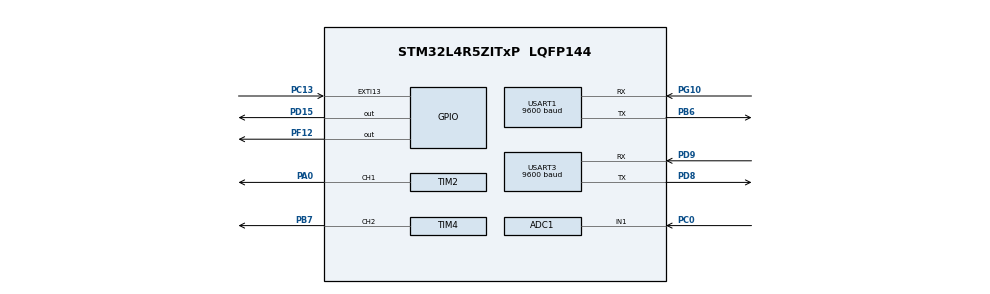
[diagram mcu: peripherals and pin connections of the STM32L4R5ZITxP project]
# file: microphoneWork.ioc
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ADC1.AWD1HighThreshold=3289
ADC1.AWD1ITMode=ENABLE
ADC1.Channel-0\#ChannelRegularConversion=ADC_CHANNEL_1
ADC1.ClockPrescaler=ADC_CLOCK_ASYNC_DIV32
ADC1.ContinuousConvMode=ENABLE
ADC1.EnableAnalogWatchDog1=true
ADC1.EnableAnalogWatchDog2=false
ADC1.NbrOfConversionFlag=1
ADC1.OffsetNumber-0\#ChannelRegularConversion=ADC_OFFSET_NONE
ADC1.Rank-0\#ChannelRegularConversion=1
ADC1.SamplingTime-0\#ChannelRegularConversion=ADC_SAMPLETIME_640CYCLES_5
ADC1.WatchdogChannel=ADC_CHANNEL_1
ADC1.master=1
Mcu.Family=STM32L4
Mcu.Name=STM32L4R5ZITxP
Mcu.Package=LQFP144
NVIC.ADC1_IRQn=true\:0\:0\:false\:false\:true\:true\:true\:true
NVIC.EXTI15_10_IRQn=true\:0\:0\:false\:false\:true\:true\:true\:true
NVIC.PriorityGroup=NVIC_PRIORITYGROUP_4
PA0.Signal=S_TIM2_CH1
PA1.Signal=ADCx_IN6
PA10.Signal=USB_OTG_FS_ID
PA13\ (JTMS/SWDIO).Signal=SYS_JTMS-SWDIO
PA14\ (JTCK/SWCLK).Signal=SYS_JTCK-SWCLK
PA3.Signal=ADCx_IN8
PA4.Signal=SPI1_NSS
PA5.Signal=SPI1_SCK
PA6.Signal=SPI1_MISO
PA7.Signal=SPI1_MOSI
PA8.Signal=USB_OTG_FS_SOF
PA9.Signal=USB_OTG_FS_VBUS
PB0.Signal=S_TIM3_CH3
PB1.Signal=ADCx_IN16
PB10.Signal=S_TIM2_CH3
PB12.Signal=SAI2_FS_A
PB13.Signal=SAI2_SCK_A
PB14.Signal=S_TIM15_CH1
PB15.Signal=SAI2_SD_A
PB2.Signal=COMP1_INP
PB3\ (JTDO/TRACESWO).Signal=SPI3_SCK
PB4\ (NJTRST).Signal=SPI3_MISO
PB5.Signal=SPI3_MOSI
PB6.Mode=Asynchronous
PB6.Signal=USART1_TX
PB7.Signal=S_TIM4_CH2
PB8.Signal=I2C1_SCL
PB9.Signal=I2C1_SDA
PC0.Signal=ADCx_IN1
PC1.Signal=ADCx_IN2
PC10.Signal=SDMMC1_D2
PC11.Signal=SDMMC1_D3
PC12.Signal=SDMMC1_CK
PC13.Signal=GPXTI13
PC14-OSC32_IN\ (PC14).Signal=RCC_OSC32_IN
PC15-OSC32_OUT\ (PC15).Signal=RCC_OSC32_OUT
PC2.Signal=ADCx_IN3
PC3.Signal=ADCx_IN4
PC4.Signal=ADCx_IN13
PC5.Signal=ADCx_IN14
PC6.Signal=SAI2_MCLK_A
PC7.Signal=S_TIM3_CH2
PC8.Signal=SDMMC1_D0
PC9.Signal=SDMMC1_D1
PD0.Signal=CAN1_RX
PD14.Signal=S_TIM4_CH3
PD15.Signal=GPIO_Output
PD2.Signal=SDMMC1_CMD
PD3.Signal=USART2_CTS
PD4.Signal=USART2_RTS
PD5.Signal=USART2_TX
PD6.Signal=USART2_RX
PD8.Mode=Asynchronous
PD8.Signal=USART3_TX
PD9.Mode=Asynchronous
PD9.Signal=USART3_RX
PE0.Signal=S_TIM4_ETR
PE10.Signal=TIM1_CH2N
PE11.Signal=S_TIM1_CH2
PE12.Signal=TIM1_CH3N
PE13.Signal=S_TIM1_CH3
PE14.Signal=TIM1_BKIN2
PE15.Signal=TIM1_BKIN
PE2.Signal=SAI1_MCLK_A
PE3.Signal=SAI1_SD_B
PE7.Signal=S_TIM1_ETR
PE8.Signal=TIM1_CH1N
PF0.Signal=I2C2_SDA
PF1.Signal=I2C2_SCL
PF12.Signal=GPIO_Output
PF2.Signal=I2C2_SMBA
PF7.Signal=SAI1_MCLK_B
PG10.Mode=Asynchronous
PG10.Signal=USART1_RX
PG7.Signal=LPUART1_TX
PG8.Signal=LPUART1_RX
PH0-OSC_IN\ (PH0).Signal=RCC_OSC_IN
PH1-OSC_OUT\ (PH1).Signal=RCC_OSC_OUT
ProjectManager.HeapSize=0x200
ProjectManager.StackSize=0x400
ProjectManager.TargetToolchain=STM32CubeIDE
RCC.ADCFreq_Value=32000000
RCC.HSE_VALUE=8000000
RCC.HSI48_VALUE=48000000
RCC.HSI_VALUE=16000000
RCC.LSE_VALUE=32768
RCC.MSI_VALUE=4000000
RCC.PLLSAI1N=16
RCC.USBFreq_Value=32000000
RCC.VCOOutputFreq_Value=32000000
SH.ADCx_IN1.0=ADC1_IN1,IN1-Single-Ended
SH.ADCx_IN13.0=ADC1_IN13
SH.ADCx_IN14.0=ADC1_IN14
SH.ADCx_IN16.0=ADC1_IN16
SH.ADCx_IN2.0=ADC1_IN2
SH.ADCx_IN3.0=ADC1_IN3
SH.ADCx_IN4.0=ADC1_IN4
SH.ADCx_IN6.0=ADC1_IN6
SH.ADCx_IN8.0=ADC1_IN8
SH.S_TIM15_CH1.0=TIM15_CH1
SH.S_TIM1_CH2.0=TIM1_CH2
SH.S_TIM1_CH3.0=TIM1_CH3
SH.S_TIM1_ETR.0=TIM1_ETR
SH.S_TIM2_CH1.0=TIM2_CH1,PWM Generation1 CH1
SH.S_TIM2_CH3.0=TIM2_CH3
SH.S_TIM3_CH2.0=TIM3_CH2
SH.S_TIM3_CH3.0=TIM3_CH3
SH.S_TIM4_CH2.0=TIM4_CH2,PWM Generation2 CH2
SH.S_TIM4_CH3.0=TIM4_CH3
SH.S_TIM4_ETR.0=TIM4_ETR
TIM2.Channel-PWM\ Generation1\ CH1=TIM_CHANNEL_1
TIM4.AutoReloadPreload=TIM_AUTORELOAD_PRELOAD_ENABLE
TIM4.Channel-PWM\ Generation2\ CH2=TIM_CHANNEL_2
TIM4.Prescaler=159
USART1.BaudRate=9600
USART1.FIFOMode=FIFOMODE_ENABLE
USART1.RXFIFOThreshold=RXFIFO_THRESHOLD_FULL
USART1.VirtualMode-Asynchronous=VM_ASYNC
USART3.BaudRate=9600
USART3.FIFOMode=FIFOMODE_ENABLE
USART3.RXFIFOThreshold=RXFIFO_THRESHOLD_FULL
USART3.VirtualMode-Asynchronous=VM_ASYNC
VP_IWDG_VS_IWDG.Mode=IWDG_Activate
VP_TIM4_VS_ClockSourceINT.Mode=Internal
board=NUCLEO-L4R5ZI-P

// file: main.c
/* USER CODE BEGIN Header */
/**
  ******************************************************************************
  * @file           : main.c
  * @brief          : Main program body
  ******************************************************************************
  * @attention
  *
  * Copyright (c) 2023 STMicroelectronics.
  * All rights reserved.
  *
  * This software is licensed under terms that can be found in the LICENSE file
  * in the root directory of this software component.
  * If no LICENSE file comes with this software, it is provided AS-IS.
  *
  ******************************************************************************
  */
/* USER CODE END Header */
#include "main.h"

/* USER CODE BEGIN Includes */
#include "XBEE.h"
#include "Unit.h"
#include "Typedefs.h"
/* USER CODE END Includes */

ADC_HandleTypeDef hadc1;

IWDG_HandleTypeDef hiwdg;

TIM_HandleTypeDef htim2;
TIM_HandleTypeDef htim4;

UART_HandleTypeDef huart1;
UART_HandleTypeDef huart3;

void SystemClock_Config(void);
static void MX_GPIO_Init(void);
static void MX_ADC1_Init(void);
static void MX_TIM4_Init(void);
static void MX_USART1_UART_Init(void);
static void MX_USART3_UART_Init(void);
static void MX_TIM2_Init(void);
static void MX_IWDG_Init(void);

/* USER CODE BEGIN 0 */
/*
void SwitchOn(void){
	HAL_GPIO_WritePin(GPIOE, GPIO_PIN_9, GPIO_PIN_SET); //dir ccw
	int threshold = 180;
	for(int i = 0; i < threshold; i++){
		HAL_GPIO_WritePin(GPIOF, GPIO_PIN_13, GPIO_PIN_SET); //step
		HAL_Delay(1);
		HAL_GPIO_WritePin(GPIOF, GPIO_PIN_13, GPIO_PIN_RESET); //step
	}
}

void SwitchOff(void){
	HAL_GPIO_WritePin(GPIOE, GPIO_PIN_9, GPIO_PIN_RESET); //dir cw
	int threshold = 180;
	for(int i = 0; i < threshold; i++){
		HAL_GPIO_WritePin(GPIOF, GPIO_PIN_13, GPIO_PIN_SET); //step
		HAL_Delay(1);
		HAL_GPIO_WritePin(GPIOF, GPIO_PIN_13, GPIO_PIN_RESET); //step
	}
}
*/

/* USER CODE END 0 */

int main(void)
{

  /* MCU Configuration--------------------------------------------------------*/

  /* Reset of all peripherals, Initializes the Flash interface and the Systick. */
  HAL_Init();

  /* Configure the system clock */
  SystemClock_Config();

  /* Initialize all configured peripherals */
  MX_GPIO_Init();
  MX_ADC1_Init();
  MX_TIM4_Init();
  MX_USART1_UART_Init();
  MX_USART3_UART_Init();
  MX_TIM2_Init();
  MX_IWDG_Init();
  /* USER CODE BEGIN 2 */

  //HAL_ADC_Start_IT(&hadc1);
  HAL_ADC_Start(&hadc1);//start conversion
  //HAL_ADC_PollForConversion(&hadc1, 0xFFFFFFFF);//wait for conversion to finish

  unit_main(&huart3);
  /*
  uint32_t ADC_VAL = 0;
  double ADC_V = 0.0;
  uint32_t state = 0;
  uint32_t next_state = 0;
  HAL_TIM_PWM_Start(&htim4, TIM_CHANNEL_2);

  */

  /* USER CODE END 2 */

  /* Infinite loop */
  while (1)
  {

    /* USER CODE BEGIN 3 */
	  //stepper code
	  //SwitchOn();
	  //SwitchOff();

	  // microphone code

	  /*
	  HAL_ADC_Start(&hadc1);//start conversion
	  HAL_ADC_PollForConversion(&hadc1, 0xFFFFFFFF);//wait for conversion to finish
	  ADC_VAL = HAL_ADC_GetValue(&hadc1);//retrieve value

	  ADC_V = (ADC_VAL * 3.3 / (1 << 12));
	  int i = 0;
	  double amplitude = fabs(ADC_V - (3.3/2));

	  if(amplitude > 1){
		  //printf("Clap!\r\n");
		  if(state == 0) next_state = 1;
		  if(state == 2) next_state = 3;
	  }
	  else if(state == 2 && TIM4->CNT > 50000){
		  next_state = 0;
		  //printf("No second clap detected\r\n");
	  }
	  if(state == 1){
		  HAL_Delay(100);
		  next_state = 2;
		  TIM4->CNT = 0;
	  }
	  if(state == 3){
		  HAL_Delay(2000);
		  //printf("Toggle switch!\r\n");
		  SwitchOn();
		  SwitchOff();
		  next_state = 0;
	  }
	  state = next_state;
	  //printf("ADC: %f\r\n", ADC_V);
	  */

  }
  /* USER CODE END 3 */
}

void SystemClock_Config(void)
{
  RCC_OscInitTypeDef RCC_OscInitStruct = {0};
  RCC_ClkInitTypeDef RCC_ClkInitStruct = {0};

  /** Configure the main internal regulator output voltage
  */
  if (HAL_PWREx_ControlVoltageScaling(PWR_REGULATOR_VOLTAGE_SCALE1) != HAL_OK)
  {
    Error_Handler();
  }

  /** Initializes the RCC Oscillators according to the specified parameters
  * in the RCC_OscInitTypeDef structure.
  */
  RCC_OscInitStruct.OscillatorType = RCC_OSCILLATORTYPE_LSI|RCC_OSCILLATORTYPE_MSI;
  RCC_OscInitStruct.LSIState = RCC_LSI_ON;
  RCC_OscInitStruct.MSIState = RCC_MSI_ON;
  RCC_OscInitStruct.MSICalibrationValue = 0;
  RCC_OscInitStruct.MSIClockRange = RCC_MSIRANGE_6;
  RCC_OscInitStruct.PLL.PLLState = RCC_PLL_NONE;
  if (HAL_RCC_OscConfig(&RCC_OscInitStruct) != HAL_OK)
  {
    Error_Handler();
  }

  /** Initializes the CPU, AHB and APB buses clocks
  */
  RCC_ClkInitStruct.ClockType = RCC_CLOCKTYPE_HCLK|RCC_CLOCKTYPE_SYSCLK
                              |RCC_CLOCKTYPE_PCLK1|RCC_CLOCKTYPE_PCLK2;
  RCC_ClkInitStruct.SYSCLKSource = RCC_SYSCLKSOURCE_MSI;
  RCC_ClkInitStruct.AHBCLKDivider = RCC_SYSCLK_DIV1;
  RCC_ClkInitStruct.APB1CLKDivider = RCC_HCLK_DIV1;
  RCC_ClkInitStruct.APB2CLKDivider = RCC_HCLK_DIV1;

  if (HAL_RCC_ClockConfig(&RCC_ClkInitStruct, FLASH_LATENCY_0) != HAL_OK)
  {
    Error_Handler();
  }
}

static void MX_ADC1_Init(void)
{

  ADC_AnalogWDGConfTypeDef AnalogWDGConfig = {0};
  ADC_ChannelConfTypeDef sConfig = {0};

  /** Common config
  */
  hadc1.Instance = ADC1;
  hadc1.Init.ClockPrescaler = ADC_CLOCK_ASYNC_DIV32;
  hadc1.Init.Resolution = ADC_RESOLUTION_12B;
  hadc1.Init.DataAlign = ADC_DATAALIGN_RIGHT;
  hadc1.Init.ScanConvMode = ADC_SCAN_DISABLE;
  hadc1.Init.EOCSelection = ADC_EOC_SINGLE_CONV;
  hadc1.Init.LowPowerAutoWait = DISABLE;
  hadc1.Init.ContinuousConvMode = ENABLE;
  hadc1.Init.NbrOfConversion = 1;
  hadc1.Init.DiscontinuousConvMode = DISABLE;
  hadc1.Init.ExternalTrigConv = ADC_SOFTWARE_START;
  hadc1.Init.ExternalTrigConvEdge = ADC_EXTERNALTRIGCONVEDGE_NONE;
  hadc1.Init.DMAContinuousRequests = DISABLE;
  hadc1.Init.Overrun = ADC_OVR_DATA_PRESERVED;
  hadc1.Init.OversamplingMode = DISABLE;
  hadc1.Init.DFSDMConfig = ADC_DFSDM_MODE_ENABLE;
  if (HAL_ADC_Init(&hadc1) != HAL_OK)
  {
    Error_Handler();
  }

  /** Configure Analog WatchDog 1
  */
  AnalogWDGConfig.WatchdogNumber = ADC_ANALOGWATCHDOG_1;
  AnalogWDGConfig.WatchdogMode = ADC_ANALOGWATCHDOG_SINGLE_REG;
  AnalogWDGConfig.Channel = ADC_CHANNEL_1;
  AnalogWDGConfig.ITMode = ENABLE;
  AnalogWDGConfig.HighThreshold = 3289;
  AnalogWDGConfig.LowThreshold = 0;
  if (HAL_ADC_AnalogWDGConfig(&hadc1, &AnalogWDGConfig) != HAL_OK)
  {
    Error_Handler();
  }

  /** Configure Regular Channel
  */
  sConfig.Channel = ADC_CHANNEL_1;
  sConfig.Rank = ADC_REGULAR_RANK_1;
  sConfig.SamplingTime = ADC_SAMPLETIME_640CYCLES_5;
  sConfig.SingleDiff = ADC_SINGLE_ENDED;
  sConfig.OffsetNumber = ADC_OFFSET_NONE;
  sConfig.Offset = 0;
  if (HAL_ADC_ConfigChannel(&hadc1, &sConfig) != HAL_OK)
  {
    Error_Handler();
  }

}

static void MX_IWDG_Init(void)
{

  hiwdg.Instance = IWDG;
  hiwdg.Init.Prescaler = IWDG_PRESCALER_4;
  hiwdg.Init.Window = 4095;
  hiwdg.Init.Reload = 4095;
  if (HAL_IWDG_Init(&hiwdg) != HAL_OK)
  {
    Error_Handler();
  }

}

static void MX_TIM2_Init(void)
{

  TIM_MasterConfigTypeDef sMasterConfig = {0};
  TIM_OC_InitTypeDef sConfigOC = {0};

  htim2.Instance = TIM2;
  htim2.Init.Prescaler = 0;
  htim2.Init.CounterMode = TIM_COUNTERMODE_UP;
  htim2.Init.Period = 4294967295;
  htim2.Init.ClockDivision = TIM_CLOCKDIVISION_DIV1;
  htim2.Init.AutoReloadPreload = TIM_AUTORELOAD_PRELOAD_DISABLE;
  if (HAL_TIM_PWM_Init(&htim2) != HAL_OK)
  {
    Error_Handler();
  }
  sMasterConfig.MasterOutputTrigger = TIM_TRGO_RESET;
  sMasterConfig.MasterSlaveMode = TIM_MASTERSLAVEMODE_DISABLE;
  if (HAL_TIMEx_MasterConfigSynchronization(&htim2, &sMasterConfig) != HAL_OK)
  {
    Error_Handler();
  }
  sConfigOC.OCMode = TIM_OCMODE_PWM1;
  sConfigOC.Pulse = 0;
  sConfigOC.OCPolarity = TIM_OCPOLARITY_HIGH;
  sConfigOC.OCFastMode = TIM_OCFAST_DISABLE;
  if (HAL_TIM_PWM_ConfigChannel(&htim2, &sConfigOC, TIM_CHANNEL_1) != HAL_OK)
  {
    Error_Handler();
  }
  HAL_TIM_MspPostInit(&htim2);

}

static void MX_TIM4_Init(void)
{

  TIM_ClockConfigTypeDef sClockSourceConfig = {0};
  TIM_MasterConfigTypeDef sMasterConfig = {0};
  TIM_OC_InitTypeDef sConfigOC = {0};

  htim4.Instance = TIM4;
  htim4.Init.Prescaler = 159;
  htim4.Init.CounterMode = TIM_COUNTERMODE_UP;
  htim4.Init.Period = 65535;
  htim4.Init.ClockDivision = TIM_CLOCKDIVISION_DIV1;
  htim4.Init.AutoReloadPreload = TIM_AUTORELOAD_PRELOAD_ENABLE;
  if (HAL_TIM_Base_Init(&htim4) != HAL_OK)
  {
    Error_Handler();
  }
  sClockSourceConfig.ClockSource = TIM_CLOCKSOURCE_INTERNAL;
  if (HAL_TIM_ConfigClockSource(&htim4, &sClockSourceConfig) != HAL_OK)
  {
    Error_Handler();
  }
  if (HAL_TIM_PWM_Init(&htim4) != HAL_OK)
  {
    Error_Handler();
  }
  sMasterConfig.MasterOutputTrigger = TIM_TRGO_RESET;
  sMasterConfig.MasterSlaveMode = TIM_MASTERSLAVEMODE_DISABLE;
  if (HAL_TIMEx_MasterConfigSynchronization(&htim4, &sMasterConfig) != HAL_OK)
  {
    Error_Handler();
  }
  sConfigOC.OCMode = TIM_OCMODE_PWM1;
  sConfigOC.Pulse = 0;
  sConfigOC.OCPolarity = TIM_OCPOLARITY_HIGH;
  sConfigOC.OCFastMode = TIM_OCFAST_DISABLE;
  if (HAL_TIM_PWM_ConfigChannel(&htim4, &sConfigOC, TIM_CHANNEL_2) != HAL_OK)
  {
    Error_Handler();
  }
  HAL_TIM_MspPostInit(&htim4);

}

static void MX_USART1_UART_Init(void)
{

  huart1.Instance = USART1;
  huart1.Init.BaudRate = 9600;
  huart1.Init.WordLength = UART_WORDLENGTH_8B;
  huart1.Init.StopBits = UART_STOPBITS_1;
  huart1.Init.Parity = UART_PARITY_NONE;
  huart1.Init.Mode = UART_MODE_TX_RX;
  huart1.Init.HwFlowCtl = UART_HWCONTROL_NONE;
  huart1.Init.OverSampling = UART_OVERSAMPLING_16;
  huart1.Init.OneBitSampling = UART_ONE_BIT_SAMPLE_DISABLE;
  huart1.Init.ClockPrescaler = UART_PRESCALER_DIV1;
  huart1.AdvancedInit.AdvFeatureInit = UART_ADVFEATURE_NO_INIT;
  if (HAL_UART_Init(&huart1) != HAL_OK)
  {
    Error_Handler();
  }
  if (HAL_UARTEx_SetTxFifoThreshold(&huart1, UART_TXFIFO_THRESHOLD_1_8) != HAL_OK)
  {
    Error_Handler();
  }
  if (HAL_UARTEx_SetRxFifoThreshold(&huart1, UART_RXFIFO_THRESHOLD_8_8) != HAL_OK)
  {
    Error_Handler();
  }
  if (HAL_UARTEx_EnableFifoMode(&huart1) != HAL_OK)
  {
    Error_Handler();
  }

}

static void MX_USART3_UART_Init(void)
{

  huart3.Instance = USART3;
  huart3.Init.BaudRate = 9600;
  huart3.Init.WordLength = UART_WORDLENGTH_8B;
  huart3.Init.StopBits = UART_STOPBITS_1;
  huart3.Init.Parity = UART_PARITY_NONE;
  huart3.Init.Mode = UART_MODE_TX_RX;
  huart3.Init.HwFlowCtl = UART_HWCONTROL_NONE;
  huart3.Init.OverSampling = UART_OVERSAMPLING_16;
  huart3.Init.OneBitSampling = UART_ONE_BIT_SAMPLE_DISABLE;
  huart3.Init.ClockPrescaler = UART_PRESCALER_DIV1;
  huart3.AdvancedInit.AdvFeatureInit = UART_ADVFEATURE_NO_INIT;
  if (HAL_UART_Init(&huart3) != HAL_OK)
  {
    Error_Handler();
  }
  if (HAL_UARTEx_SetTxFifoThreshold(&huart3, UART_TXFIFO_THRESHOLD_1_8) != HAL_OK)
  {
    Error_Handler();
  }
  if (HAL_UARTEx_SetRxFifoThreshold(&huart3, UART_RXFIFO_THRESHOLD_8_8) != HAL_OK)
  {
    Error_Handler();
  }
  if (HAL_UARTEx_EnableFifoMode(&huart3) != HAL_OK)
  {
    Error_Handler();
  }

}

static void MX_GPIO_Init(void)
{
  GPIO_InitTypeDef GPIO_InitStruct = {0};

  /* GPIO Ports Clock Enable */
  __HAL_RCC_GPIOE_CLK_ENABLE();
  __HAL_RCC_GPIOC_CLK_ENABLE();
  __HAL_RCC_GPIOF_CLK_ENABLE();
  __HAL_RCC_GPIOH_CLK_ENABLE();
  __HAL_RCC_GPIOA_CLK_ENABLE();
  __HAL_RCC_GPIOB_CLK_ENABLE();
  __HAL_RCC_GPIOD_CLK_ENABLE();
  __HAL_RCC_GPIOG_CLK_ENABLE();
  HAL_PWREx_EnableVddIO2();

  /*Configure GPIO pin Output Level */
  HAL_GPIO_WritePin(GPIOF, GPIO_PIN_12, GPIO_PIN_RESET);

  /*Configure GPIO pin Output Level */
  HAL_GPIO_WritePin(GPIOD, GPIO_PIN_15, GPIO_PIN_RESET);

  /*Configure GPIO pins : PE2 PE3 */
  GPIO_InitStruct.Pin = GPIO_PIN_2|GPIO_PIN_3;
  GPIO_InitStruct.Mode = GPIO_MODE_AF_PP;
  GPIO_InitStruct.Pull = GPIO_NOPULL;
  GPIO_InitStruct.Speed = GPIO_SPEED_FREQ_LOW;
  GPIO_InitStruct.Alternate = GPIO_AF13_SAI1;
  HAL_GPIO_Init(GPIOE, &GPIO_InitStruct);

  /*Configure GPIO pin : PC13 */
  GPIO_InitStruct.Pin = GPIO_PIN_13;
  GPIO_InitStruct.Mode = GPIO_MODE_IT_RISING;
  GPIO_InitStruct.Pull = GPIO_NOPULL;
  HAL_GPIO_Init(GPIOC, &GPIO_InitStruct);

  /*Configure GPIO pins : PF0 PF1 PF2 */
  GPIO_InitStruct.Pin = GPIO_PIN_0|GPIO_PIN_1|GPIO_PIN_2;
  GPIO_InitStruct.Mode = GPIO_MODE_AF_OD;
  GPIO_InitStruct.Pull = GPIO_NOPULL;
  GPIO_InitStruct.Speed = GPIO_SPEED_FREQ_VERY_HIGH;
  GPIO_InitStruct.Alternate = GPIO_AF4_I2C2;
  HAL_GPIO_Init(GPIOF, &GPIO_InitStruct);

  /*Configure GPIO pin : PF7 */
  GPIO_InitStruct.Pin = GPIO_PIN_7;
  GPIO_InitStruct.Mode = GPIO_MODE_AF_PP;
  GPIO_InitStruct.Pull = GPIO_NOPULL;
  GPIO_InitStruct.Speed = GPIO_SPEED_FREQ_LOW;
  GPIO_InitStruct.Alternate = GPIO_AF13_SAI1;
  HAL_GPIO_Init(GPIOF, &GPIO_InitStruct);

  /*Configure GPIO pins : PA4 PA5 PA6 PA7 */
  GPIO_InitStruct.Pin = GPIO_PIN_4|GPIO_PIN_5|GPIO_PIN_6|GPIO_PIN_7;
  GPIO_InitStruct.Mode = GPIO_MODE_AF_PP;
  GPIO_InitStruct.Pull = GPIO_NOPULL;
  GPIO_InitStruct.Speed = GPIO_SPEED_FREQ_VERY_HIGH;
  GPIO_InitStruct.Alternate = GPIO_AF5_SPI1;
  HAL_GPIO_Init(GPIOA, &GPIO_InitStruct);

  /*Configure GPIO pin : PB0 */
  GPIO_InitStruct.Pin = GPIO_PIN_0;
  GPIO_InitStruct.Mode = GPIO_MODE_AF_PP;
  GPIO_InitStruct.Pull = GPIO_NOPULL;
  GPIO_InitStruct.Speed = GPIO_SPEED_FREQ_LOW;
  GPIO_InitStruct.Alternate = GPIO_AF2_TIM3;
  HAL_GPIO_Init(GPIOB, &GPIO_InitStruct);

  /*Configure GPIO pin : PB2 */
  GPIO_InitStruct.Pin = GPIO_PIN_2;
  GPIO_InitStruct.Mode = GPIO_MODE_ANALOG;
  GPIO_InitStruct.Pull = GPIO_NOPULL;
  HAL_GPIO_Init(GPIOB, &GPIO_InitStruct);

  /*Configure GPIO pin : PF12 */
  GPIO_InitStruct.Pin = GPIO_PIN_12;
  GPIO_InitStruct.Mode = GPIO_MODE_OUTPUT_PP;
  GPIO_InitStruct.Pull = GPIO_NOPULL;
  GPIO_InitStruct.Speed = GPIO_SPEED_FREQ_LOW;
  HAL_GPIO_Init(GPIOF, &GPIO_InitStruct);

  /*Configure GPIO pins : PE7 PE8 PE10 PE11
                           PE12 PE13 */
  GPIO_InitStruct.Pin = GPIO_PIN_7|GPIO_PIN_8|GPIO_PIN_10|GPIO_PIN_11
                          |GPIO_PIN_12|GPIO_PIN_13;
  GPIO_InitStruct.Mode = GPIO_MODE_AF_PP;
  GPIO_InitStruct.Pull = GPIO_NOPULL;
  GPIO_InitStruct.Speed = GPIO_SPEED_FREQ_LOW;
  GPIO_InitStruct.Alternate = GPIO_AF1_TIM1;
  HAL_GPIO_Init(GPIOE, &GPIO_InitStruct);

  /*Configure GPIO pins : PE14 PE15 */
  GPIO_InitStruct.Pin = GPIO_PIN_14|GPIO_PIN_15;
  GPIO_InitStruct.Mode = GPIO_MODE_AF_PP;
  GPIO_InitStruct.Pull = GPIO_NOPULL;
  GPIO_InitStruct.Speed = GPIO_SPEED_FREQ_LOW;
  GPIO_InitStruct.Alternate = GPIO_AF3_TIM1_COMP1;
  HAL_GPIO_Init(GPIOE, &GPIO_InitStruct);

  /*Configure GPIO pins : PB12 PB13 PB15 */
  GPIO_InitStruct.Pin = GPIO_PIN_12|GPIO_PIN_13|GPIO_PIN_15;
  GPIO_InitStruct.Mode = GPIO_MODE_AF_PP;
  GPIO_InitStruct.Pull = GPIO_NOPULL;
  GPIO_InitStruct.Speed = GPIO_SPEED_FREQ_LOW;
  GPIO_InitStruct.Alternate = GPIO_AF13_SAI2;
  HAL_GPIO_Init(GPIOB, &GPIO_InitStruct);

  /*Configure GPIO pin : PB14 */
  GPIO_InitStruct.Pin = GPIO_PIN_14;
  GPIO_InitStruct.Mode = GPIO_MODE_AF_PP;
  GPIO_InitStruct.Pull = GPIO_NOPULL;
  GPIO_InitStruct.Speed = GPIO_SPEED_FREQ_LOW;
  GPIO_InitStruct.Alternate = GPIO_AF14_TIM15;
  HAL_GPIO_Init(GPIOB, &GPIO_InitStruct);

  /*Configure GPIO pin : PD15 */
  GPIO_InitStruct.Pin = GPIO_PIN_15;
  GPIO_InitStruct.Mode = GPIO_MODE_OUTPUT_PP;
  GPIO_InitStruct.Pull = GPIO_NOPULL;
  GPIO_InitStruct.Speed = GPIO_SPEED_FREQ_LOW;
  HAL_GPIO_Init(GPIOD, &GPIO_InitStruct);

  /*Configure GPIO pins : PG7 PG8 */
  GPIO_InitStruct.Pin = GPIO_PIN_7|GPIO_PIN_8;
  GPIO_InitStruct.Mode = GPIO_MODE_AF_PP;
  GPIO_InitStruct.Pull = GPIO_NOPULL;
  GPIO_InitStruct.Speed = GPIO_SPEED_FREQ_VERY_HIGH;
  GPIO_InitStruct.Alternate = GPIO_AF8_LPUART1;
  HAL_GPIO_Init(GPIOG, &GPIO_InitStruct);

  /*Configure GPIO pin : PC6 */
  GPIO_InitStruct.Pin = GPIO_PIN_6;
  GPIO_InitStruct.Mode = GPIO_MODE_AF_PP;
  GPIO_InitStruct.Pull = GPIO_NOPULL;
  GPIO_InitStruct.Speed = GPIO_SPEED_FREQ_LOW;
  GPIO_InitStruct.Alternate = GPIO_AF13_SAI2;
  HAL_GPIO_Init(GPIOC, &GPIO_InitStruct);

  /*Configure GPIO pin : PC7 */
  GPIO_InitStruct.Pin = GPIO_PIN_7;
  GPIO_InitStruct.Mode = GPIO_MODE_AF_PP;
  GPIO_InitStruct.Pull = GPIO_NOPULL;
  GPIO_InitStruct.Speed = GPIO_SPEED_FREQ_LOW;
  GPIO_InitStruct.Alternate = GPIO_AF2_TIM3;
  HAL_GPIO_Init(GPIOC, &GPIO_InitStruct);

  /*Configure GPIO pins : PC8 PC9 PC10 PC11
                           PC12 */
  GPIO_InitStruct.Pin = GPIO_PIN_8|GPIO_PIN_9|GPIO_PIN_10|GPIO_PIN_11
                          |GPIO_PIN_12;
  GPIO_InitStruct.Mode = GPIO_MODE_AF_PP;
  GPIO_InitStruct.Pull = GPIO_NOPULL;
  GPIO_InitStruct.Speed = GPIO_SPEED_FREQ_VERY_HIGH;
  GPIO_InitStruct.Alternate = GPIO_AF12_SDMMC1;
  HAL_GPIO_Init(GPIOC, &GPIO_InitStruct);

  /*Configure GPIO pins : PA8 PA10 */
  GPIO_InitStruct.Pin = GPIO_PIN_8|GPIO_PIN_10;
  GPIO_InitStruct.Mode = GPIO_MODE_AF_PP;
  GPIO_InitStruct.Pull = GPIO_NOPULL;
  GPIO_InitStruct.Speed = GPIO_SPEED_FREQ_VERY_HIGH;
  GPIO_InitStruct.Alternate = GPIO_AF10_OTG_FS;
  HAL_GPIO_Init(GPIOA, &GPIO_InitStruct);

  /*Configure GPIO pin : PA9 */
  GPIO_InitStruct.Pin = GPIO_PIN_9;
  GPIO_InitStruct.Mode = GPIO_MODE_INPUT;
  GPIO_InitStruct.Pull = GPIO_NOPULL;
  HAL_GPIO_Init(GPIOA, &GPIO_InitStruct);

  /*Configure GPIO pin : PD0 */
  GPIO_InitStruct.Pin = GPIO_PIN_0;
  GPIO_InitStruct.Mode = GPIO_MODE_AF_PP;
  GPIO_InitStruct.Pull = GPIO_NOPULL;
  GPIO_InitStruct.Speed = GPIO_SPEED_FREQ_VERY_HIGH;
  GPIO_InitStruct.Alternate = GPIO_AF9_CAN1;
  HAL_GPIO_Init(GPIOD, &GPIO_InitStruct);

  /*Configure GPIO pin : PD2 */
  GPIO_InitStruct.Pin = GPIO_PIN_2;
  GPIO_InitStruct.Mode = GPIO_MODE_AF_PP;
  GPIO_InitStruct.Pull = GPIO_NOPULL;
  GPIO_InitStruct.Speed = GPIO_SPEED_FREQ_VERY_HIGH;
  GPIO_InitStruct.Alternate = GPIO_AF12_SDMMC1;
  HAL_GPIO_Init(GPIOD, &GPIO_InitStruct);

  /*Configure GPIO pins : PD3 PD4 PD5 PD6 */
  GPIO_InitStruct.Pin = GPIO_PIN_3|GPIO_PIN_4|GPIO_PIN_5|GPIO_PIN_6;
  GPIO_InitStruct.Mode = GPIO_MODE_AF_PP;
  GPIO_InitStruct.Pull = GPIO_NOPULL;
  GPIO_InitStruct.Speed = GPIO_SPEED_FREQ_VERY_HIGH;
  GPIO_InitStruct.Alternate = GPIO_AF7_USART2;
  HAL_GPIO_Init(GPIOD, &GPIO_InitStruct);

  /*Configure GPIO pins : PB3 PB4 PB5 */
  GPIO_InitStruct.Pin = GPIO_PIN_3|GPIO_PIN_4|GPIO_PIN_5;
  GPIO_InitStruct.Mode = GPIO_MODE_AF_PP;
  GPIO_InitStruct.Pull = GPIO_NOPULL;
  GPIO_InitStruct.Speed = GPIO_SPEED_FREQ_VERY_HIGH;
  GPIO_InitStruct.Alternate = GPIO_AF6_SPI3;
  HAL_GPIO_Init(GPIOB, &GPIO_InitStruct);

  /*Configure GPIO pins : PB8 PB9 */
  GPIO_InitStruct.Pin = GPIO_PIN_8|GPIO_PIN_9;
  GPIO_InitStruct.Mode = GPIO_MODE_AF_OD;
  GPIO_InitStruct.Pull = GPIO_NOPULL;
  GPIO_InitStruct.Speed = GPIO_SPEED_FREQ_VERY_HIGH;
  GPIO_InitStruct.Alternate = GPIO_AF4_I2C1;
  HAL_GPIO_Init(GPIOB, &GPIO_InitStruct);

  /* EXTI interrupt init*/
  HAL_NVIC_SetPriority(EXTI15_10_IRQn, 0, 0);
  HAL_NVIC_EnableIRQ(EXTI15_10_IRQn);

}

/* USER CODE BEGIN 4 */
#ifdef __GNUC__
#define PUTCHAR_PROTOTYPE int __io_putchar(int ch)
#else
  #define PUTCHAR_PROTOTYPE int fputc(int ch, FILE *f)
#endif /* __GNUC__ */
PUTCHAR_PROTOTYPE
{
  HAL_UART_Transmit(&huart1, (uint8_t *)&ch, 1, 0xFFFF);
  return ch;
}
/* USER CODE END 4 */

void Error_Handler(void)
{
  __disable_irq();
  while (1)
  {
  }
}
